# CY8C3866AXI_040 register map
File version: 0.1
CY8C38
Registers are 8-bit, read-write, no defined reset value unless marked. A register's access mark holds for its fields unless they carry their own. Offsets are from the block's base; lines under a group give offsets from that group; [hi:lo] are bit positions; {n}, {i} and the like mark numbered series; 'fields as' and 'values as' point back to an identical list; <NAME> marks a mode.

## Memory map
0x00006400 HMC5883L_I2C size 0x85
0x00006429 CONFIG_COM size 0x140 — UART
0x00006468 DATA_COM size 0xFF — UART

## CONFIG_COM — UART
Base 0x00006429
0x00 RX_CONFIG_COM_RX_ADDRESS1 — RX Address1 Register
0x10 RX_CONFIG_COM_RX_ADDRESS2 — RX Address2 Register
0x20 RX_CONFIG_COM_RX_DATA — RX Data Register
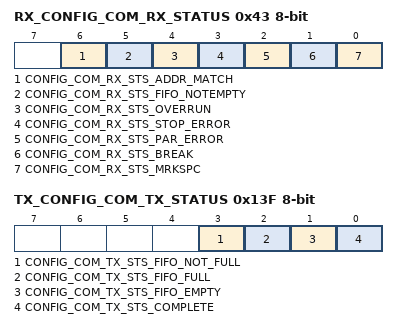
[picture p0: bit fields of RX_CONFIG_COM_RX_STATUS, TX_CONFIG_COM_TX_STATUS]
0x43 RX_CONFIG_COM_RX_STATUS — RX status register
  [6] CONFIG_COM_RX_STS_ADDR_MATCH ro, [5] CONFIG_COM_RX_STS_FIFO_NOTEMPTY ro, [4] CONFIG_COM_RX_STS_OVERRUN ro, [3] CONFIG_COM_RX_STS_STOP_ERROR ro, [2] CONFIG_COM_RX_STS_PAR_ERROR ro, [1] CONFIG_COM_RX_STS_BREAK ro, [0] CONFIG_COM_RX_STS_MRKSPC ro
0x11F TX_CONFIG_COM_TX_DATA — TX Data Register
0x13F TX_CONFIG_COM_TX_STATUS — TX status register
  [3] CONFIG_COM_TX_STS_FIFO_NOT_FULL ro, [2] CONFIG_COM_TX_STS_FIFO_FULL ro, [1] CONFIG_COM_TX_STS_FIFO_EMPTY ro, [0] CONFIG_COM_TX_STS_COMPLETE ro

## DATA_COM — UART
Base 0x00006468
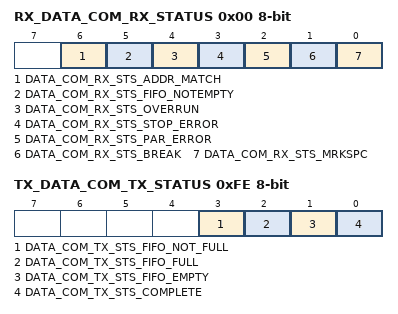
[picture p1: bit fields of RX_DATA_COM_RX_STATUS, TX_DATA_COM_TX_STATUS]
0x00 RX_DATA_COM_RX_STATUS — RX status register
  [6] DATA_COM_RX_STS_ADDR_MATCH ro, [5] DATA_COM_RX_STS_FIFO_NOTEMPTY ro, [4] DATA_COM_RX_STS_OVERRUN ro, [3] DATA_COM_RX_STS_STOP_ERROR ro, [2] DATA_COM_RX_STS_PAR_ERROR ro, [1] DATA_COM_RX_STS_BREAK ro, [0] DATA_COM_RX_STS_MRKSPC ro
0xC1 RX_DATA_COM_RX_ADDRESS1 — RX Address1 Register
0xD1 RX_DATA_COM_RX_ADDRESS2 — RX Address2 Register
0xDE TX_DATA_COM_TX_DATA — TX Data Register
0xE1 RX_DATA_COM_RX_DATA — RX Data Register
0xFE TX_DATA_COM_TX_STATUS — TX status register
  [3] DATA_COM_TX_STS_FIFO_NOT_FULL ro, [2] DATA_COM_TX_STS_FIFO_FULL ro, [1] DATA_COM_TX_STS_FIFO_EMPTY ro, [0] DATA_COM_TX_STS_COMPLETE ro

## HMC5883L_I2C
Base 0x00006400
0x00 HMC5883L_I2C_UDB_MSTR_DATA — Data
  [7:0] data — This register provides read/write access to the Shift register.
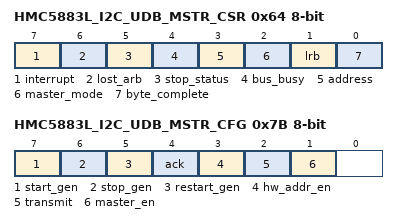
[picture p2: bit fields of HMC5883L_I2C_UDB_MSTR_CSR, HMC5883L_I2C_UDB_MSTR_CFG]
0x64 HMC5883L_I2C_UDB_MSTR_CSR — Status Register
  [7] interrupt ro — Interrupt bit
  [6] lost_arb ro
  [5] stop_status
  [4] bus_busy ro
  [3] address ro
  [2] master_mode ro
  [1] lrb ro
  [0] byte_complete ro
0x7B HMC5883L_I2C_UDB_MSTR_CFG — Configuration Register
  [7] start_gen, [6] stop_gen, [5] restart_gen, [4] ack, [3] hw_addr_en, [2] transmit, [1] master_en
0x84 HMC5883L_I2C_UDB_MSTR_INT_MASK — Interrupt Mask
